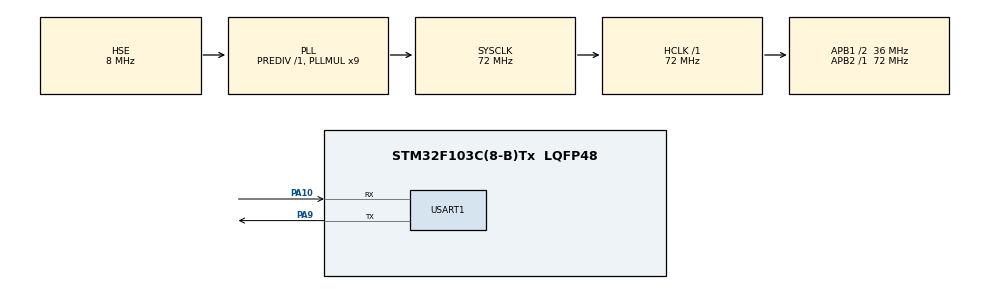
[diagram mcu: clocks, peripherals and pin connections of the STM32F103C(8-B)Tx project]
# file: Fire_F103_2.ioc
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ADC1.Channel-0\#ChannelRegularConversion=ADC_CHANNEL_TEMPSENSOR
ADC1.ExternalTrigConv=ADC_EXTERNALTRIGCONV_T3_TRGO
ADC1.NbrOfConversionFlag=1
ADC1.Rank-0\#ChannelRegularConversion=1
ADC1.SamplingTime-0\#ChannelRegularConversion=ADC_SAMPLETIME_55CYCLES_5
ADC1.master=1
Mcu.Family=STM32F1
Mcu.Name=STM32F103C(8-B)Tx
Mcu.Package=LQFP48
NVIC.PriorityGroup=NVIC_PRIORITYGROUP_4
PA10.Mode=Asynchronous
PA10.Signal=USART1_RX
PA13.Mode=Serial_Wire
PA13.Signal=SYS_JTMS-SWDIO
PA14.Mode=Serial_Wire
PA14.Signal=SYS_JTCK-SWCLK
PA9.Mode=Asynchronous
PA9.Signal=USART1_TX
PC14-OSC32_IN.Mode=LSE-External-Oscillator
PC14-OSC32_IN.Signal=RCC_OSC32_IN
PC15-OSC32_OUT.Mode=LSE-External-Oscillator
PC15-OSC32_OUT.Signal=RCC_OSC32_OUT
PD0-OSC_IN.Mode=HSE-External-Oscillator
PD0-OSC_IN.Signal=RCC_OSC_IN
PD1-OSC_OUT.Mode=HSE-External-Oscillator
PD1-OSC_OUT.Signal=RCC_OSC_OUT
ProjectManager.HeapSize=0x200
ProjectManager.StackSize=0x400
ProjectManager.TargetToolchain=MDK-ARM V5.32
RCC.ADCPresc=RCC_ADCPCLK2_DIV6
RCC.AHBFreq_Value=72000000
RCC.APB1CLKDivider=RCC_HCLK_DIV2
RCC.APB1Freq_Value=36000000
RCC.APB1TimFreq_Value=72000000
RCC.APB2Freq_Value=72000000
RCC.APB2TimFreq_Value=72000000
RCC.HCLKFreq_Value=72000000
RCC.PLLMUL=RCC_PLL_MUL9
RCC.PLLSourceVirtual=RCC_PLLSOURCE_HSE
RCC.SYSCLKFreq_VALUE=72000000
RCC.SYSCLKSource=RCC_SYSCLKSOURCE_PLLCLK
RCC.USBFreq_Value=72000000
TIM3.Period=5000-1
TIM3.Prescaler=7200-1
TIM3.TIM_MasterOutputTrigger=TIM_TRGO_UPDATE
USART1.VirtualMode=VM_ASYNC
VP_ADC1_TempSens_Input.Mode=IN-TempSens
VP_TIM3_VS_ClockSourceINT.Mode=Internal
board=custom

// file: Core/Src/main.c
/* USER CODE BEGIN Header */
/**
  ******************************************************************************
  * @file           : main.c
  * @brief          : Main program body
  ******************************************************************************
  * @attention
  *
  * Copyright (c) 2026 STMicroelectronics.
  * All rights reserved.
  *
  * This software is licensed under terms that can be found in the LICENSE file
  * in the root directory of this software component.
  * If no LICENSE file comes with this software, it is provided AS-IS.
  *
  ******************************************************************************
  */
/* USER CODE END Header */
#include "main.h"
#include "adc.h"
#include "tim.h"
#include "usart.h"
#include "gpio.h"

/* USER CODE BEGIN Includes */
#include <stdio.h>//使用printf函数

/* USER CODE END Includes */

/* USER CODE BEGIN PV */
uint32_t adc_val=0;//存储原始值
float voltage =0.0f;//存储电压值
float tem=0.0f;//存储温度值

/* USER CODE END PV */

void SystemClock_Config(void);

int main(void)
{

  /* MCU Configuration--------------------------------------------------------*/

  /* Reset of all peripherals, Initializes the Flash interface and the Systick. */
  HAL_Init();

  /* Configure the system clock */
  SystemClock_Config();

  /* Initialize all configured peripherals */
  MX_GPIO_Init();
  MX_ADC1_Init();
  MX_TIM3_Init();
  MX_USART1_UART_Init();
  /* USER CODE BEGIN 2 */
	//启动ADC 校准
	HAL_ADCEx_Calibration_Start(&hadc1);

	//启动ADC转换
	HAL_ADC_Start(&hadc1);

	//启动TIM3基础定时
	HAL_TIM_Base_Start(&htim3);

	//等待芯片稳定
	HAL_Delay(3000);

  /* USER CODE END 2 */

  /* Infinite loop */
  /* USER CODE BEGIN WHILE */
  while (1)
  {

		if(HAL_ADC_PollForConversion(&hadc1,HAL_MAX_DELAY)==HAL_OK )//轮询等待ADC转换完成
		{
			adc_val=HAL_ADC_GetValue(&hadc1);//读取原始值
			voltage=(float)adc_val/4095*3.3f;//将原始值转换为电压值（单位v）
			tem=(1.43-voltage) / 0.0043+25;//将电压值转换为芯片内部温度（单位c）
			printf("当前芯片内部温度为：%.3fC",tem);
		}
    /* USER CODE END WHILE */

  }
}

void SystemClock_Config(void)
{
  RCC_OscInitTypeDef RCC_OscInitStruct = {0};
  RCC_ClkInitTypeDef RCC_ClkInitStruct = {0};
  RCC_PeriphCLKInitTypeDef PeriphClkInit = {0};

  /** Initializes the RCC Oscillators according to the specified parameters
  * in the RCC_OscInitTypeDef structure.
  */
  RCC_OscInitStruct.OscillatorType = RCC_OSCILLATORTYPE_HSE;
  RCC_OscInitStruct.HSEState = RCC_HSE_ON;
  RCC_OscInitStruct.HSEPredivValue = RCC_HSE_PREDIV_DIV1;
  RCC_OscInitStruct.HSIState = RCC_HSI_ON;
  RCC_OscInitStruct.PLL.PLLState = RCC_PLL_ON;
  RCC_OscInitStruct.PLL.PLLSource = RCC_PLLSOURCE_HSE;
  RCC_OscInitStruct.PLL.PLLMUL = RCC_PLL_MUL9;
  if (HAL_RCC_OscConfig(&RCC_OscInitStruct) != HAL_OK)
  {
    Error_Handler();
  }

  /** Initializes the CPU, AHB and APB buses clocks
  */
  RCC_ClkInitStruct.ClockType = RCC_CLOCKTYPE_HCLK|RCC_CLOCKTYPE_SYSCLK
                              |RCC_CLOCKTYPE_PCLK1|RCC_CLOCKTYPE_PCLK2;
  RCC_ClkInitStruct.SYSCLKSource = RCC_SYSCLKSOURCE_PLLCLK;
  RCC_ClkInitStruct.AHBCLKDivider = RCC_SYSCLK_DIV1;
  RCC_ClkInitStruct.APB1CLKDivider = RCC_HCLK_DIV2;
  RCC_ClkInitStruct.APB2CLKDivider = RCC_HCLK_DIV1;

  if (HAL_RCC_ClockConfig(&RCC_ClkInitStruct, FLASH_LATENCY_2) != HAL_OK)
  {
    Error_Handler();
  }
  PeriphClkInit.PeriphClockSelection = RCC_PERIPHCLK_ADC;
  PeriphClkInit.AdcClockSelection = RCC_ADCPCLK2_DIV6;
  if (HAL_RCCEx_PeriphCLKConfig(&PeriphClkInit) != HAL_OK)
  {
    Error_Handler();
  }
}

/* USER CODE BEGIN 4 */
int fputc(int ch, FILE*f)
{
	HAL_UART_Transmit(&huart1,(uint8_t*)&ch,1 , HAL_MAX_DELAY);
	return ch;

}

/* USER CODE END 4 */

void Error_Handler(void)
{
  __disable_irq();
  while (1)
  {
  }
}
